VERSION "created by canmatrix"

NS_ :

BS_: 500000

BU_:

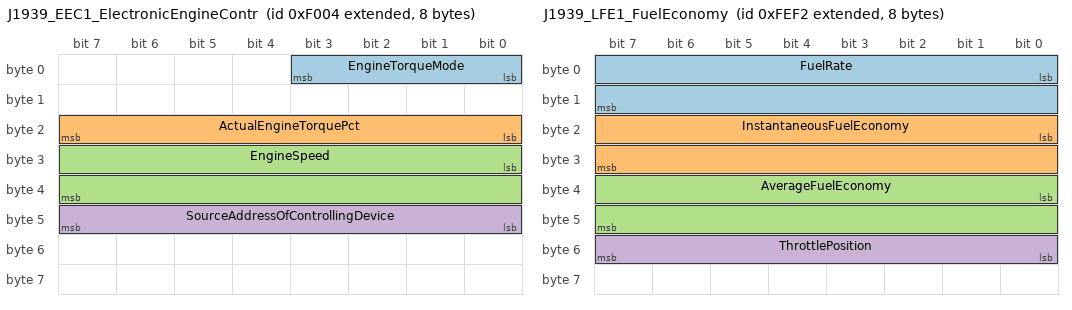
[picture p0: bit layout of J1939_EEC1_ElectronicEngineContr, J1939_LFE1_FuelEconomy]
BO_ 2147545092 J1939_EEC1_ElectronicEngineContr: 8 Vector__XXX
 SG_ EngineTorqueMode : 0|4@1+ (1,0) [0|15] "" Vector__XXX
 SG_ ActualEngineTorquePct : 16|8@1+ (1,-125) [-125|130] "%" Vector__XXX
 SG_ EngineSpeed : 24|16@1+ (0.125,0) [0.000|8191.875] "rpm" Vector__XXX
 SG_ SourceAddressOfControllingDevice : 40|8@1+ (1,0) [0|255] "" Vector__XXX

BO_ 2147548914 J1939_LFE1_FuelEconomy: 8 Vector__XXX
 SG_ FuelRate : 0|16@1+ (0.05000000000000000277555756156289135105907917022705078125,0) [0E-056|3276.750000000000181896164797] "L/h" Vector__XXX
 SG_ InstantaneousFuelEconomy : 16|16@1+ (0.00195300000000000009182932192430826034978963434696197509765625,0) [0E-062|127.9898550000000060180346123] "km/L" Vector__XXX
 SG_ AverageFuelEconomy : 32|16@1+ (0.00195300000000000009182932192430826034978963434696197509765625,0) [0E-062|127.9898550000000060180346123] "km/L" Vector__XXX
 SG_ ThrottlePosition : 48|8@1+ (0.40000000000000002220446049250313080847263336181640625,0) [0E-053|102.0000000000000056621374256] "%" Vector__XXX

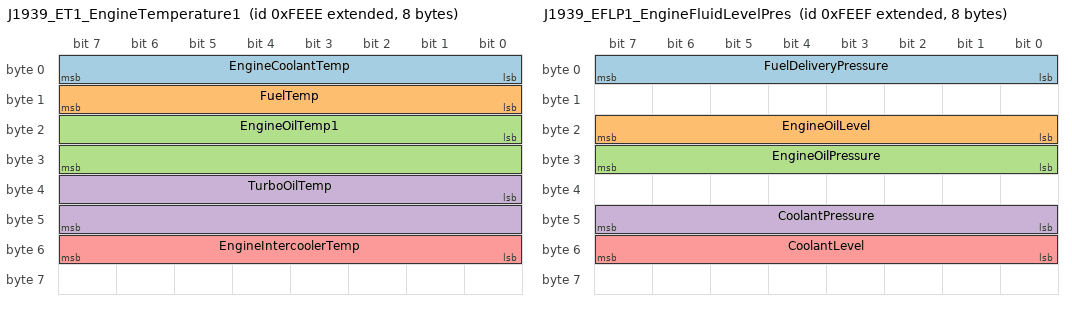
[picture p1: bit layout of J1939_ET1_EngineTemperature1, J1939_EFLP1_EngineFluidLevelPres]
BO_ 2147548910 J1939_ET1_EngineTemperature1: 8 Vector__XXX
 SG_ EngineCoolantTemp : 0|8@1+ (1,-40) [-40|215] "°C" Vector__XXX
 SG_ FuelTemp : 8|8@1+ (1,-40) [-40|215] "°C" Vector__XXX
 SG_ EngineOilTemp1 : 16|16@1+ (0.03125,-273) [-273.00000|1774.96875] "°C" Vector__XXX
 SG_ TurboOilTemp : 32|16@1+ (0.03125,-273) [-273.00000|1774.96875] "°C" Vector__XXX
 SG_ EngineIntercoolerTemp : 48|8@1+ (1,-40) [-40|215] "°C" Vector__XXX

BO_ 2147548911 J1939_EFLP1_EngineFluidLevelPres: 8 Vector__XXX
 SG_ FuelDeliveryPressure : 0|8@1+ (4,0) [0|1020] "kPa" Vector__XXX
 SG_ EngineOilLevel : 16|8@1+ (0.40000000000000002220446049250313080847263336181640625,0) [0E-053|102.0000000000000056621374256] "%" Vector__XXX
 SG_ EngineOilPressure : 24|8@1+ (4,0) [0|1020] "kPa" Vector__XXX
 SG_ CoolantPressure : 40|8@1+ (2,0) [0|510] "kPa" Vector__XXX
 SG_ CoolantLevel : 48|8@1+ (0.40000000000000002220446049250313080847263336181640625,0) [0E-053|102.0000000000000056621374256] "%" Vector__XXX

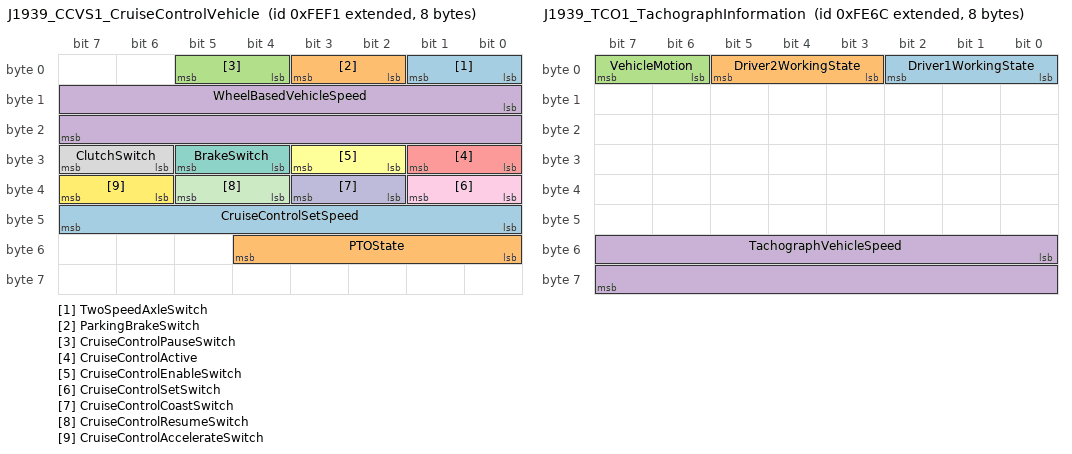
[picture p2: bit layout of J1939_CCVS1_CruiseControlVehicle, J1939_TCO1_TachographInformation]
BO_ 2147548913 J1939_CCVS1_CruiseControlVehicle: 8 Vector__XXX
 SG_ TwoSpeedAxleSwitch : 0|2@1+ (1,0) [0|3] "" Vector__XXX
 SG_ ParkingBrakeSwitch : 2|2@1+ (1,0) [0|3] "" Vector__XXX
 SG_ CruiseControlPauseSwitch : 4|2@1+ (1,0) [0|3] "" Vector__XXX
 SG_ WheelBasedVehicleSpeed : 8|16@1+ (0.0039060000000000001836586438486165206995792686939239501953125,0) [0E-061|255.9797100000000120360692246] "km/h" Vector__XXX
 SG_ CruiseControlActive : 24|2@1+ (1,0) [0|3] "" Vector__XXX
 SG_ CruiseControlEnableSwitch : 26|2@1+ (1,0) [0|3] "" Vector__XXX
 SG_ BrakeSwitch : 28|2@1+ (1,0) [0|3] "" Vector__XXX
 SG_ ClutchSwitch : 30|2@1+ (1,0) [0|3] "" Vector__XXX
 SG_ CruiseControlSetSwitch : 32|2@1+ (1,0) [0|3] "" Vector__XXX
 SG_ CruiseControlCoastSwitch : 34|2@1+ (1,0) [0|3] "" Vector__XXX
 SG_ CruiseControlResumeSwitch : 36|2@1+ (1,0) [0|3] "" Vector__XXX
 SG_ CruiseControlAccelerateSwitch : 38|2@1+ (1,0) [0|3] "" Vector__XXX
 SG_ CruiseControlSetSpeed : 40|8@1+ (1,0) [0|255] "km/h" Vector__XXX
 SG_ PTOState : 48|5@1+ (1,0) [0|31] "" Vector__XXX

BO_ 2147548780 J1939_TCO1_TachographInformation: 8 Vector__XXX
 SG_ Driver1WorkingState : 0|3@1+ (1,0) [0|7] "" Vector__XXX
 SG_ Driver2WorkingState : 3|3@1+ (1,0) [0|7] "" Vector__XXX
 SG_ VehicleMotion : 6|2@1+ (1,0) [0|3] "" Vector__XXX
 SG_ TachographVehicleSpeed : 48|16@1+ (0.0039060000000000001836586438486165206995792686939239501953125,0) [0E-061|255.9797100000000120360692246] "km/h" Vector__XXX

BO_ 2147548901 J1939_HOURS_EngineHours: 8 Vector__XXX
 SG_ EngineTotalHoursOfOperation : 0|32@1+ (0.05000000000000000277555756156289135105907917022705078125,0) [0E-056|214748364.7500000119209289523] "h" Vector__XXX
 SG_ EngineTotalRevolutions : 32|32@1+ (1000,0) [0|4294967295000] "r" Vector__XXX

BO_ 2147548908 J1939_VI_VehicleIdentification: 8 Vector__XXX
 SG_ VIN_Char01 : 0|8@1+ (1,0) [0|255] "" Vector__XXX

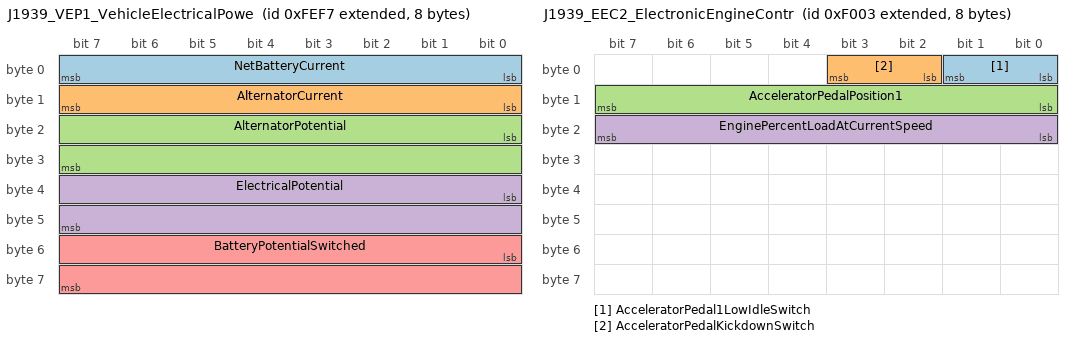
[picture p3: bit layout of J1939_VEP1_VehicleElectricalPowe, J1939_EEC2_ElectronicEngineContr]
BO_ 2147548919 J1939_VEP1_VehicleElectricalPowe: 8 Vector__XXX
 SG_ NetBatteryCurrent : 0|8@1+ (1,-125) [-125|130] "A" Vector__XXX
 SG_ AlternatorCurrent : 8|8@1+ (1,0) [0|255] "A" Vector__XXX
 SG_ AlternatorPotential : 16|16@1+ (0.05000000000000000277555756156289135105907917022705078125,0) [0E-056|3276.750000000000181896164797] "V" Vector__XXX
 SG_ ElectricalPotential : 32|16@1+ (0.05000000000000000277555756156289135105907917022705078125,0) [0E-056|3276.750000000000181896164797] "V" Vector__XXX
 SG_ BatteryPotentialSwitched : 48|16@1+ (0.05000000000000000277555756156289135105907917022705078125,0) [0E-056|3276.750000000000181896164797] "V" Vector__XXX

BO_ 2147548540 J1939_DEF_DieselExhaustFluidConc: 8 Vector__XXX
 SG_ DEFTankLevel : 0|8@1+ (0.40000000000000002220446049250313080847263336181640625,0) [0E-053|102.0000000000000056621374256] "%" Vector__XXX
 SG_ DEFTankTemperature : 8|8@1+ (1,-40) [-40|215] "°C" Vector__XXX

BO_ 2147548899 J1939_EC1_EngineConfiguration1: 8 Vector__XXX
 SG_ EngineSpeedAtIdle : 0|16@1+ (0.125,0) [0.000|8191.875] "rpm" Vector__XXX
 SG_ EngineSpeedAtMaxIdlePoint1 : 24|16@1+ (0.125,0) [0.000|8191.875] "rpm" Vector__XXX

BO_ 2147548895 J1939_EEC3_ElectronicEngineContr: 8 Vector__XXX
 SG_ EngineDemandPercentTorque : 56|8@1+ (1,-125) [-125|130] "%" Vector__XXX

BO_ 2147545091 J1939_EEC2_ElectronicEngineContr: 8 Vector__XXX
 SG_ AcceleratorPedal1LowIdleSwitch : 0|2@1+ (1,0) [0|3] "" Vector__XXX
 SG_ AcceleratorPedalKickdownSwitch : 2|2@1+ (1,0) [0|3] "" Vector__XXX
 SG_ AcceleratorPedalPosition1 : 8|8@1+ (0.40000000000000002220446049250313080847263336181640625,0) [0E-053|102.0000000000000056621374256] "%" Vector__XXX
 SG_ EnginePercentLoadAtCurrentSpeed : 16|8@1+ (1,0) [0|255] "%" Vector__XXX

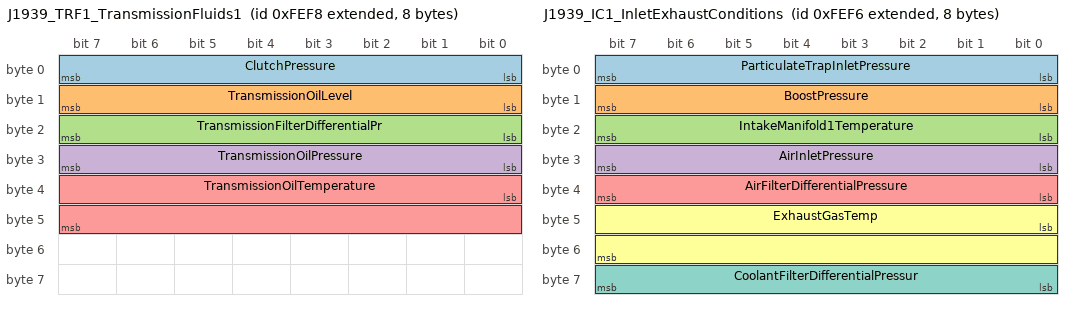
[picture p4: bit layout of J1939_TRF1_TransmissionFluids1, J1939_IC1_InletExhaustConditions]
BO_ 2147548920 J1939_TRF1_TransmissionFluids1: 8 Vector__XXX
 SG_ ClutchPressure : 0|8@1+ (16,0) [0|4080] "kPa" Vector__XXX
 SG_ TransmissionOilLevel : 8|8@1+ (0.40000000000000002220446049250313080847263336181640625,0) [0E-053|102.0000000000000056621374256] "%" Vector__XXX
 SG_ TransmissionFilterDifferentialPr : 16|8@1+ (2,0) [0|510] "kPa" Vector__XXX
 SG_ TransmissionOilPressure : 24|8@1+ (16,0) [0|4080] "kPa" Vector__XXX
 SG_ TransmissionOilTemperature : 32|16@1+ (0.03125,-273) [-273.00000|1774.96875] "°C" Vector__XXX

BO_ 2147548918 J1939_IC1_InletExhaustConditions: 8 Vector__XXX
 SG_ ParticulateTrapInletPressure : 0|8@1+ (0.5,0) [0|127.5] "kPa" Vector__XXX
 SG_ BoostPressure : 8|8@1+ (2,0) [0|510] "kPa" Vector__XXX
 SG_ IntakeManifold1Temperature : 16|8@1+ (1,-40) [-40|215] "°C" Vector__XXX
 SG_ AirInletPressure : 24|8@1+ (2,0) [0|510] "kPa" Vector__XXX
 SG_ AirFilterDifferentialPressure : 32|8@1+ (0.05000000000000000277555756156289135105907917022705078125,0) [0E-056|12.75000000000000070776717820] "kPa" Vector__XXX
 SG_ ExhaustGasTemp : 40|16@1+ (0.03125,-273) [-273.00000|1774.96875] "°C" Vector__XXX
 SG_ CoolantFilterDifferentialPressur : 56|8@1+ (0.5,0) [0|127.5] "kPa" Vector__XXX

BO_ 2147548338 J1939_FFE_FuelEconomyExtended: 8 Vector__XXX
 SG_ EngineTripFuel : 0|32@1+ (0.5,0) [0|2147483647.5] "L" Vector__XXX
 SG_ EngineTotalFuelUsed : 32|32@1+ (0.5,0) [0|2147483647.5] "L" Vector__XXX

BO_ 2147548865 J1939_HRVD_HighResolutionVehicle: 8 Vector__XXX
 SG_ HighResolutionTotalVehicleDistan : 0|32@1+ (5,0) [0|21474836475] "m" Vector__XXX
 SG_ HighResolutionTripDistance : 32|32@1+ (5,0) [0|21474836475] "m" Vector__XXX

CM_ BO_ 2147545092  "Engine speed, torque mode, demand torque. Source: Wikipedia SAE J1939 PGN list (en.wikipedia.org/wiki/SAE_J1939)";
CM_ BO_ 2147548914  "Fuel rate + instantaneous + average fuel economy. Source: Wikipedia SAE J1939 PGN list (en.wikipedia.org/wiki/SAE_J1939)";
CM_ BO_ 2147548910  "Coolant + fuel + engine oil + intercooler temperatures. Source: Wikipedia SAE J1939 PGN list (en.wikipedia.org/wiki/SAE_J1939)";
CM_ BO_ 2147548911  "Oil pressure/level + coolant pressure/level + fuel delivery pressure. Source: Wikipedia SAE J1939 PGN list (en.wikipedia.org/wiki/SAE_J1939)";
CM_ BO_ 2147548913  "Vehicle speed + cruise control state + brake/clutch/parking switches. Source: Wikipedia SAE J1939 PGN list (en.wikipedia.org/wiki/SAE_J1939)";
CM_ BO_ 2147548780  "Tachograph + driver state (mostly for heavy-truck FMS). Source: Wikipedia SAE J1939 PGN list (en.wikipedia.org/wiki/SAE_J1939)";
CM_ BO_ 2147548901  "Engine total hours of operation. Source: Wikipedia SAE J1939 PGN list (en.wikipedia.org/wiki/SAE_J1939)";
CM_ BO_ 2147548908  "Vehicle Identification Number (VIN). Source: Wikipedia SAE J1939 PGN list (en.wikipedia.org/wiki/SAE_J1939)";
CM_ BO_ 2147548919  "Battery + alternator + engine starter electrical state. Source: Wikipedia SAE J1939 PGN list (en.wikipedia.org/wiki/SAE_J1939)";
CM_ BO_ 2147548540  "DEF (urea) tank level + temperature + concentration. Source: Wikipedia SAE J1939 PGN list (en.wikipedia.org/wiki/SAE_J1939)";
CM_ BO_ 2147548899  "Engine configuration data — displacement, speed limits, fuel type. Source: Wikipedia SAE J1939 PGN list (en.wikipedia.org/wiki/SAE_J1939)";
CM_ BO_ 2147548895  "Engine demand percent torque + nominal friction torque. Source: Wikipedia SAE J1939 PGN list (en.wikipedia.org/wiki/SAE_J1939)";
CM_ BO_ 2147545091  "Accelerator pedal + percent load. Source: Wikipedia SAE J1939 PGN list (en.wikipedia.org/wiki/SAE_J1939)";
CM_ BO_ 2147548920  "Transmission oil + clutch pressure. Source: Wikipedia SAE J1939 PGN list (en.wikipedia.org/wiki/SAE_J1939)";
CM_ BO_ 2147548918  "Boost + intake air temp + air filter differential pressure. Source: Wikipedia SAE J1939 PGN list (en.wikipedia.org/wiki/SAE_J1939)";
CM_ BO_ 2147548338  "Trip fuel + total fuel + trip distance. Source: Wikipedia SAE J1939 PGN list (en.wikipedia.org/wiki/SAE_J1939)";
CM_ BO_ 2147548865  "High-resolution vehicle distance (HRVD per SAE J1939-71). Source: Wikipedia SAE J1939 PGN list (en.wikipedia.org/wiki/SAE_J1939)";

CM_ SG_ 2147545092 EngineTorqueMode "Per-signal source: Wikipedia SAE J1939 PGN list (en.wikipedia.org/wiki/SAE_J1939)";
CM_ SG_ 2147545092 ActualEngineTorquePct "Actual engine percent torque";
CM_ SG_ 2147545092 EngineSpeed "Per-signal source: Wikipedia SAE J1939 PGN list (en.wikipedia.org/wiki/SAE_J1939)";
CM_ SG_ 2147545092 SourceAddressOfControllingDevice "Source address of the device commanding engine torque";
CM_ SG_ 2147548914 FuelRate "Per-signal source: Wikipedia SAE J1939 PGN list (en.wikipedia.org/wiki/SAE_J1939)";
CM_ SG_ 2147548914 InstantaneousFuelEconomy "Per-signal source: Wikipedia SAE J1939 PGN list (en.wikipedia.org/wiki/SAE_J1939)";
CM_ SG_ 2147548914 AverageFuelEconomy "Per-signal source: Wikipedia SAE J1939 PGN list (en.wikipedia.org/wiki/SAE_J1939)";
CM_ SG_ 2147548914 ThrottlePosition "Per-signal source: Wikipedia SAE J1939 PGN list (en.wikipedia.org/wiki/SAE_J1939)";
CM_ SG_ 2147548910 EngineCoolantTemp "Per-signal source: Wikipedia SAE J1939 PGN list (en.wikipedia.org/wiki/SAE_J1939)";
CM_ SG_ 2147548910 FuelTemp "Per-signal source: Wikipedia SAE J1939 PGN list (en.wikipedia.org/wiki/SAE_J1939)";
CM_ SG_ 2147548910 EngineOilTemp1 "Per-signal source: Wikipedia SAE J1939 PGN list (en.wikipedia.org/wiki/SAE_J1939)";
CM_ SG_ 2147548910 TurboOilTemp "Per-signal source: Wikipedia SAE J1939 PGN list (en.wikipedia.org/wiki/SAE_J1939)";
CM_ SG_ 2147548910 EngineIntercoolerTemp "Per-signal source: Wikipedia SAE J1939 PGN list (en.wikipedia.org/wiki/SAE_J1939)";
CM_ SG_ 2147548911 FuelDeliveryPressure "Per-signal source: Wikipedia SAE J1939 PGN list (en.wikipedia.org/wiki/SAE_J1939)";
CM_ SG_ 2147548911 EngineOilLevel "Per-signal source: Wikipedia SAE J1939 PGN list (en.wikipedia.org/wiki/SAE_J1939)";
CM_ SG_ 2147548911 EngineOilPressure "Per-signal source: Wikipedia SAE J1939 PGN list (en.wikipedia.org/wiki/SAE_J1939)";
CM_ SG_ 2147548911 CoolantPressure "Per-signal source: Wikipedia SAE J1939 PGN list (en.wikipedia.org/wiki/SAE_J1939)";
CM_ SG_ 2147548911 CoolantLevel "Per-signal source: Wikipedia SAE J1939 PGN list (en.wikipedia.org/wiki/SAE_J1939)";
CM_ SG_ 2147548913 TwoSpeedAxleSwitch "Per-signal source: Wikipedia SAE J1939 PGN list (en.wikipedia.org/wiki/SAE_J1939)";
CM_ SG_ 2147548913 ParkingBrakeSwitch "Per-signal source: Wikipedia SAE J1939 PGN list (en.wikipedia.org/wiki/SAE_J1939)";
CM_ SG_ 2147548913 CruiseControlPauseSwitch "Per-signal source: Wikipedia SAE J1939 PGN list (en.wikipedia.org/wiki/SAE_J1939)";
CM_ SG_ 2147548913 WheelBasedVehicleSpeed "Per-signal source: Wikipedia SAE J1939 PGN list (en.wikipedia.org/wiki/SAE_J1939)";
CM_ SG_ 2147548913 CruiseControlActive "Per-signal source: Wikipedia SAE J1939 PGN list (en.wikipedia.org/wiki/SAE_J1939)";
CM_ SG_ 2147548913 CruiseControlEnableSwitch "Per-signal source: Wikipedia SAE J1939 PGN list (en.wikipedia.org/wiki/SAE_J1939)";
CM_ SG_ 2147548913 BrakeSwitch "Per-signal source: Wikipedia SAE J1939 PGN list (en.wikipedia.org/wiki/SAE_J1939)";
CM_ SG_ 2147548913 ClutchSwitch "Per-signal source: Wikipedia SAE J1939 PGN list (en.wikipedia.org/wiki/SAE_J1939)";
CM_ SG_ 2147548913 CruiseControlSetSwitch "Per-signal source: Wikipedia SAE J1939 PGN list (en.wikipedia.org/wiki/SAE_J1939)";
CM_ SG_ 2147548913 CruiseControlCoastSwitch "Per-signal source: Wikipedia SAE J1939 PGN list (en.wikipedia.org/wiki/SAE_J1939)";
CM_ SG_ 2147548913 CruiseControlResumeSwitch "Per-signal source: Wikipedia SAE J1939 PGN list (en.wikipedia.org/wiki/SAE_J1939)";
CM_ SG_ 2147548913 CruiseControlAccelerateSwitch "Per-signal source: Wikipedia SAE J1939 PGN list (en.wikipedia.org/wiki/SAE_J1939)";
CM_ SG_ 2147548913 CruiseControlSetSpeed "Per-signal source: Wikipedia SAE J1939 PGN list (en.wikipedia.org/wiki/SAE_J1939)";
CM_ SG_ 2147548913 PTOState "Per-signal source: Wikipedia SAE J1939 PGN list (en.wikipedia.org/wiki/SAE_J1939)";
CM_ SG_ 2147548780 Driver1WorkingState "Per-signal source: Wikipedia SAE J1939 PGN list (en.wikipedia.org/wiki/SAE_J1939)";
CM_ SG_ 2147548780 Driver2WorkingState "Per-signal source: Wikipedia SAE J1939 PGN list (en.wikipedia.org/wiki/SAE_J1939)";
CM_ SG_ 2147548780 VehicleMotion "Per-signal source: Wikipedia SAE J1939 PGN list (en.wikipedia.org/wiki/SAE_J1939)";
CM_ SG_ 2147548780 TachographVehicleSpeed "Per-signal source: Wikipedia SAE J1939 PGN list (en.wikipedia.org/wiki/SAE_J1939)";
CM_ SG_ 2147548901 EngineTotalHoursOfOperation "Per-signal source: Wikipedia SAE J1939 PGN list (en.wikipedia.org/wiki/SAE_J1939)";
CM_ SG_ 2147548901 EngineTotalRevolutions "Per-signal source: Wikipedia SAE J1939 PGN list (en.wikipedia.org/wiki/SAE_J1939)";
CM_ SG_ 2147548908 VIN_Char01 "ASCII byte 0 of VIN; full VIN spans multipacket";
CM_ SG_ 2147548919 NetBatteryCurrent "Per-signal source: Wikipedia SAE J1939 PGN list (en.wikipedia.org/wiki/SAE_J1939)";
CM_ SG_ 2147548919 AlternatorCurrent "Per-signal source: Wikipedia SAE J1939 PGN list (en.wikipedia.org/wiki/SAE_J1939)";
CM_ SG_ 2147548919 AlternatorPotential "Per-signal source: Wikipedia SAE J1939 PGN list (en.wikipedia.org/wiki/SAE_J1939)";
CM_ SG_ 2147548919 ElectricalPotential "Per-signal source: Wikipedia SAE J1939 PGN list (en.wikipedia.org/wiki/SAE_J1939)";
CM_ SG_ 2147548919 BatteryPotentialSwitched "Per-signal source: Wikipedia SAE J1939 PGN list (en.wikipedia.org/wiki/SAE_J1939)";
CM_ SG_ 2147548540 DEFTankLevel "Per-signal source: Wikipedia SAE J1939 PGN list (en.wikipedia.org/wiki/SAE_J1939)";
CM_ SG_ 2147548540 DEFTankTemperature "Per-signal source: Wikipedia SAE J1939 PGN list (en.wikipedia.org/wiki/SAE_J1939)";
CM_ SG_ 2147548899 EngineSpeedAtIdle "Per-signal source: Wikipedia SAE J1939 PGN list (en.wikipedia.org/wiki/SAE_J1939)";
CM_ SG_ 2147548899 EngineSpeedAtMaxIdlePoint1 "Per-signal source: Wikipedia SAE J1939 PGN list (en.wikipedia.org/wiki/SAE_J1939)";
CM_ SG_ 2147548895 EngineDemandPercentTorque "Per-signal source: Wikipedia SAE J1939 PGN list (en.wikipedia.org/wiki/SAE_J1939)";
CM_ SG_ 2147545091 AcceleratorPedal1LowIdleSwitch "Per-signal source: Wikipedia SAE J1939 PGN list (en.wikipedia.org/wiki/SAE_J1939)";
CM_ SG_ 2147545091 AcceleratorPedalKickdownSwitch "Per-signal source: Wikipedia SAE J1939 PGN list (en.wikipedia.org/wiki/SAE_J1939)";
CM_ SG_ 2147545091 AcceleratorPedalPosition1 "Per-signal source: Wikipedia SAE J1939 PGN list (en.wikipedia.org/wiki/SAE_J1939)";
CM_ SG_ 2147545091 EnginePercentLoadAtCurrentSpeed "Per-signal source: Wikipedia SAE J1939 PGN list (en.wikipedia.org/wiki/SAE_J1939)";
CM_ SG_ 2147548920 ClutchPressure "Per-signal source: Wikipedia SAE J1939 PGN list (en.wikipedia.org/wiki/SAE_J1939)";
CM_ SG_ 2147548920 TransmissionOilLevel "Per-signal source: Wikipedia SAE J1939 PGN list (en.wikipedia.org/wiki/SAE_J1939)";
CM_ SG_ 2147548920 TransmissionFilterDifferentialPr "Per-signal source: Wikipedia SAE J1939 PGN list (en.wikipedia.org/wiki/SAE_J1939)";
CM_ SG_ 2147548920 TransmissionOilPressure "Per-signal source: Wikipedia SAE J1939 PGN list (en.wikipedia.org/wiki/SAE_J1939)";
CM_ SG_ 2147548920 TransmissionOilTemperature "Per-signal source: Wikipedia SAE J1939 PGN list (en.wikipedia.org/wiki/SAE_J1939)";
CM_ SG_ 2147548918 ParticulateTrapInletPressure "Per-signal source: Wikipedia SAE J1939 PGN list (en.wikipedia.org/wiki/SAE_J1939)";
CM_ SG_ 2147548918 BoostPressure "Per-signal source: Wikipedia SAE J1939 PGN list (en.wikipedia.org/wiki/SAE_J1939)";
CM_ SG_ 2147548918 IntakeManifold1Temperature "Per-signal source: Wikipedia SAE J1939 PGN list (en.wikipedia.org/wiki/SAE_J1939)";
CM_ SG_ 2147548918 AirInletPressure "Per-signal source: Wikipedia SAE J1939 PGN list (en.wikipedia.org/wiki/SAE_J1939)";
CM_ SG_ 2147548918 AirFilterDifferentialPressure "Per-signal source: Wikipedia SAE J1939 PGN list (en.wikipedia.org/wiki/SAE_J1939)";
CM_ SG_ 2147548918 ExhaustGasTemp "Per-signal source: Wikipedia SAE J1939 PGN list (en.wikipedia.org/wiki/SAE_J1939)";
CM_ SG_ 2147548918 CoolantFilterDifferentialPressur "Per-signal source: Wikipedia SAE J1939 PGN list (en.wikipedia.org/wiki/SAE_J1939)";
CM_ SG_ 2147548338 EngineTripFuel "Per-signal source: Wikipedia SAE J1939 PGN list (en.wikipedia.org/wiki/SAE_J1939)";
CM_ SG_ 2147548338 EngineTotalFuelUsed "Per-signal source: Wikipedia SAE J1939 PGN list (en.wikipedia.org/wiki/SAE_J1939)";
CM_ SG_ 2147548865 HighResolutionTotalVehicleDistan "Per-signal source: Wikipedia SAE J1939 PGN list (en.wikipedia.org/wiki/SAE_J1939)";
CM_ SG_ 2147548865 HighResolutionTripDistance "Per-signal source: Wikipedia SAE J1939 PGN list (en.wikipedia.org/wiki/SAE_J1939)";

BA_DEF_ BO_ "SystemMessageLongSymbol" STRING;
BA_DEF_ SG_ "SystemSignalLongSymbol" STRING;

BA_ "SystemMessageLongSymbol" BO_ 2147545092 "J1939_EEC1_ElectronicEngineController1";
BA_ "SystemMessageLongSymbol" BO_ 2147548911 "J1939_EFLP1_EngineFluidLevelPressure1";
BA_ "SystemMessageLongSymbol" BO_ 2147548913 "J1939_CCVS1_CruiseControlVehicleSpeed1";
BA_ "SystemMessageLongSymbol" BO_ 2147548919 "J1939_VEP1_VehicleElectricalPower1";
BA_ "SystemMessageLongSymbol" BO_ 2147548540 "J1939_DEF_DieselExhaustFluidConcentration";
BA_ "SystemMessageLongSymbol" BO_ 2147548895 "J1939_EEC3_ElectronicEngineController3";
BA_ "SystemMessageLongSymbol" BO_ 2147545091 "J1939_EEC2_ElectronicEngineController2";
BA_ "SystemMessageLongSymbol" BO_ 2147548918 "J1939_IC1_InletExhaustConditions1";
BA_ "SystemMessageLongSymbol" BO_ 2147548865 "J1939_HRVD_HighResolutionVehicleDistance";

BA_ "SystemSignalLongSymbol" SG_ 2147548920 TransmissionFilterDifferentialPr "TransmissionFilterDifferentialPressure";
BA_ "SystemSignalLongSymbol" SG_ 2147548918 CoolantFilterDifferentialPressur "CoolantFilterDifferentialPressure";
BA_ "SystemSignalLongSymbol" SG_ 2147548865 HighResolutionTotalVehicleDistan "HighResolutionTotalVehicleDistance";

VAL_ 2147545092 EngineTorqueMode 0 "LowIdleGovernor" 1 "AcceleratorPedal" 2 "CruiseControl" 3 "PTOGovernor" 4 "RoadSpeedGovernor" 5 "ASRControl" 6 "TransmissionControl" 7 "ABSControl" 8 "TorqueLimiting" 9 "HighSpeedGovernor" 10 "BrakingSystem" 11 "RemoteAccelerator" 14 "Other" 15 "NotAvailable";
